# ESP32C6_RADIO register map
File version: 0.1.0
Registers are 32-bit, read-write, no defined reset value unless marked. A register's access mark holds for its fields unless they carry their own. Offsets are from the block's base; [hi:lo] are bit positions.

## HP_SYS — SRAM bank ownership
Base 0x60095000; register names take the prefix HP_SYSTEM_
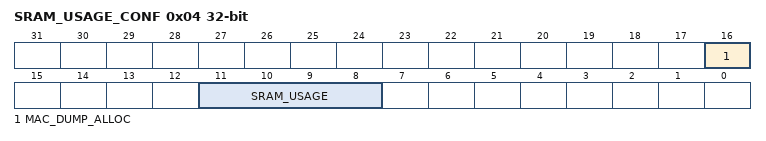
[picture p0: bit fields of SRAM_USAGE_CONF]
0x04 SRAM_USAGE_CONF — Hands an SRAM block to the dump engine Other bits: documented 0 The library saves the register and restores it after each use. Undocumented behaviour: - While the engine owns a block the CPUs cannot reach any of it, so nothing else may live there; the linker snippet reserves the block and lowers `_heap_sentry`. The engine owns the whole 128 KiB block during a capture, although a capture uses at most 64 KiB, so the library's other buffers live in block 3. - On the RISC-V core the switch must land before the engine starts: a `fence rw, rw` and a read-back follow each write. - Block 3 ends in the ROM's .bss and .data (0x4087e610 to 0x40880000), which ROM functions use at any time: it is never the engine's. A Zephyr image with Wi-Fi fills blocks 0 and 1 (the C6 build of `apps/rfprobe` has `_end` at 0x408366b0 and its libc heap above that up to block 2), so with Wi-Fi only block 2 can be the engine's. Without the Wi-Fi driver (the PHY brought up alone, `CONFIG_ESP_SDR_PHY_ONLY`) an image fits block 0 and block 1 works as a bank too (bit 9): upstream's rotation over blocks 1 and 2 then runs, the switch one write of this register between units. Evidence: `lib/esp_sdr/src/esp_sdr_rx.c:246-278`, `lib/esp_sdr/src/esp_sdr.c:123-133` (save and restore) Evidence: *measured* bench 2026-10-08, `lib/esp_sdr/esp_sdr_bank_c6.ld:32-35` (whole block) Evidence: *working* `lib/esp_sdr/src/esp_sdr_rx.c:262-265, 274-277` (fence) Evidence: *measured* build 2026-10-11 (only block 2 with Wi-Fi); `modules/zephyr/soc/espressif/esp32c6/memory.h:29-40` (ROM .bss and .data); `lib/esp_sdr/esp_sdr_bank_c6.ld:47-48` (`_heap_sentry`, rfprobe heap) Evidence: *measured* bench 2026-10-21 (block 1 as a bank, a PHY-only image with `_end` at 0x40817620; the rotation 120 s without an error); `lib/esp_sdr/esp_sdr_bank_c6.ld`, `lib/esp_sdr/src/esp_sdr_gapless.c`
  [16] MAC_DUMP_ALLOC — Adds a 64 KiB offset (HAL). The library leaves it 0; upstream's ring clears it. Evidence: `modules/hal/espressif/components/soc/esp32c6/register/soc/hp_system_reg.h:63-68`
  [11:8] SRAM_USAGE — One-hot: field bit n (register bit 8 + n) hands block n, 0x40800000 + n x 128 KiB, to the engine, for capture and playback alike; 0 gives every block back to the CPUs. n = 2 (0x40840000, the stock `adctrig()` bank) is the capture bank. The HAL says "0: cpu use hp-memory, 1: mac-dump accessing hp-memory". Evidence: `modules/hal/espressif/components/soc/esp32c6/register/soc/hp_system_reg.h:46-62`

## MODEM_SYSCON — Modem clocks and reset Documented registers; the entries give the behaviour the HAL does not document.
Base 0x600A9800
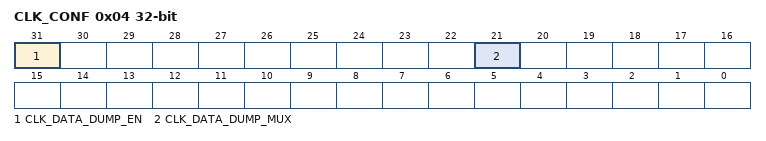
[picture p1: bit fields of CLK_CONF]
0x04 CLK_CONF — Modem clock enables, forced on for the dump engine Other bits: documented 30:22 The dump engine needs this register, MODEM_SYSCON_CLK_CONF1_REG and MODEM_SYSCON_CLK_CONF_POWER_ST_REG forced on before each capture and each playback, as the vendor's `rftest_init()`/`phy_set_clk_conf()` does. The library writes 0xffffffff here, then 0x7ffff to MODEM_SYSCON_CLK_CONF1_REG, then 0xffffffff to MODEM_SYSCON_CLK_CONF_POWER_ST_REG. What playback needs besides: see DUMP_DAC_TRIG_REG. Evidence: *working* `lib/esp_sdr/src/esp_sdr_rx.c:255-257`; *measured* bench 2026-10-11 (playback); *upstream* `modules/lib/esp-sdr/main/targets/esp32c6/chip.h:35-36`; `modules/hal/espressif/components/soc/esp32c6/include/modem/modem_syscon_reg.h:21-27, 82-87`
  [31] CLK_DATA_DUMP_EN — Written 1 with the rest of the register (0xffffffff).
  [21] CLK_DATA_DUMP_MUX — Written 1 with the rest of the register (0xffffffff).
0x0C CLK_CONF_POWER_ST — Forced to 0xffffffff for the dump engine Other bits: documented 31:8 Written 0xffffffff before each capture and each playback, the last of the three clock writes (see MODEM_SYSCON_CLK_CONF_REG). Evidence: *working* `lib/esp_sdr/src/esp_sdr_rx.c:255-257`; *measured* bench 2026-10-11 (playback); *upstream* `modules/lib/esp-sdr/main/targets/esp32c6/chip.h:35-36`; `modules/hal/espressif/components/soc/esp32c6/include/modem/modem_syscon_reg.h:151`
0x10 MODEM_RST_CONF — Modem resets, pulsed at boot against stale modem state Other bits: documented 31:29, 27:24, 22, 18:14, 10, 8 Undocumented: the modem subsystem keeps the previous firmware's state across a chip reset (USB-Serial-JTAG, esptool). The library writes 0xffffffff, then 0, here and 0xf, then 0, to MODEM_LPCON_RST_CONF_REG at `PRE_KERNEL_1`, before the Wi-Fi driver starts, through `modem_syscon_ll_reset_all()` and `modem_lpcon_ll_reset_all()`, as ESP-IDF's `esp_system_reset_modules_on_exit()` does on a restart. Evidence: *measured* bench 2026-10-09 (symptoms under "Stale modem state"); *working* `lib/esp_sdr/src/esp_sdr.c:29-48`; `modules/hal/espressif/components/hal/esp32c6/include/hal/modem_syscon_ll.h:325-329`, `modules/hal/espressif/components/esp_system/port/soc/esp32c6/system_internal.c:45-46`
0x14 CLK_CONF1 — Bits 18:0 forced on for the dump engine Other bits: documented 23:0 Bits 18:0 written 1 (0x7ffff) before each capture and each playback, the second of the three clock writes (see MODEM_SYSCON_CLK_CONF_REG). Evidence: *working* `lib/esp_sdr/src/esp_sdr_rx.c:255-257`; *measured* bench 2026-10-11 (playback); *upstream* `modules/lib/esp-sdr/main/targets/esp32c6/chip.h:35-36`; `modules/hal/espressif/components/soc/esp32c6/include/modem/modem_syscon_reg.h:281`
0x1C WIFI_BB_CFG — Wi-Fi baseband configuration; the 802.11p clock mode in bits 4:2
  [31:0] WIFI_BB_CFG — Bits 4:2: `phy_11p_set(1, m)` writes 4 for m = 0, else 5, presumably for 10 and 5 MHz channels, and clears AGC_R30_REG bit 5. Whether the dump follows the slower clock is unknown (a lead under "Dump and DAC engine"). Evidence: *decompile* C6 `libphy.a` `phy_feature.o`
